# STM32G07x register map
File version: 1.3
CPU: CM0+ r0p0, little endian, no MPU, no FPU, 3 interrupt priority bits
Registers are 32-bit, read-write, reset 0x0 unless marked. A register's access mark holds for its fields unless they carry their own. Offsets are from the block's base; [hi:lo] are bit positions; 'fields as' and 'values as' point back to an identical list.

## RTC — Real-time clock
Base 0x40002800
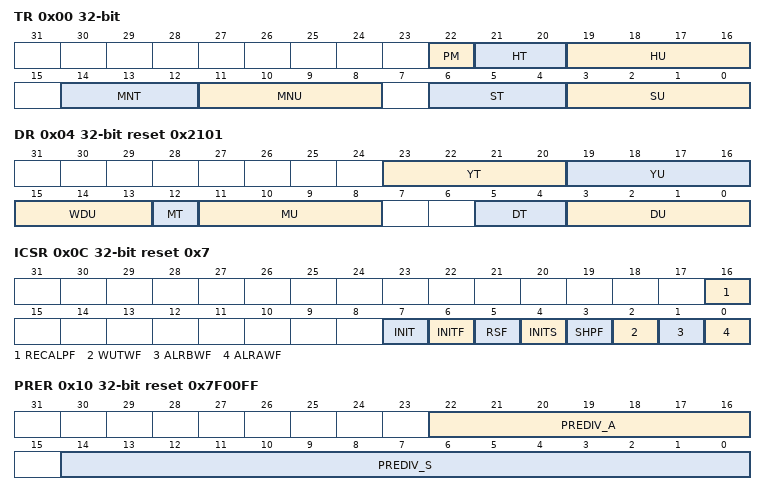
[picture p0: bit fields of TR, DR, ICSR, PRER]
0x00 TR — time register
  [22] PM — AM/PM notation
  [21:20] HT — Hour tens in BCD format
  [19:16] HU — Hour units in BCD format
  [14:12] MNT — Minute tens in BCD format
  [11:8] MNU — Minute units in BCD format
  [6:4] ST — Second tens in BCD format
  [3:0] SU — Second units in BCD format
0x04 DR reset 0x2101 — date register
  [23:20] YT — Year tens in BCD format
  [19:16] YU — Year units in BCD format
  [15:13] WDU — Week day units
  [12] MT — Month tens in BCD format
  [11:8] MU — Month units in BCD format
  [5:4] DT — Date tens in BCD format
  [3:0] DU — Date units in BCD format
0x08 SSR ro — sub second register
  [15:0] SS — Sub second value
0x0C ICSR access per field reset 0x7 — initialization and status register
  [16] RECALPF ro — Recalibration pending Flag
  [7] INIT rw — Initialization mode
  [6] INITF ro — Initialization flag
  [5] RSF rw — Registers synchronization flag
  [4] INITS ro — Initialization status flag
  [3] SHPF rw — Shift operation pending
  [2] WUTWF ro — Wakeup timer write flag
  [1] ALRBWF ro — Alarm B write flag
  [0] ALRAWF ro — Alarm A write flag
0x10 PRER reset 0x7F00FF — prescaler register
  [22:16] PREDIV_A — Asynchronous prescaler factor
  [14:0] PREDIV_S — Synchronous prescaler factor
0x14 WUTR reset 0xFFFF — wakeup timer register
  [15:0] WUT — Wakeup auto-reload value bits
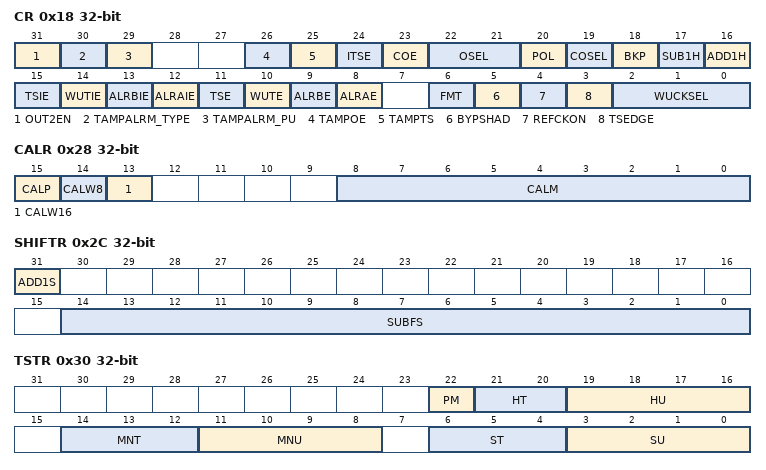
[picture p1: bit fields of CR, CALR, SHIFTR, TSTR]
0x18 CR — control register
  [31] OUT2EN, [30] TAMPALRM_TYPE, [29] TAMPALRM_PU, [26] TAMPOE, [25] TAMPTS, [24] ITSE, [23] COE, [22:21] OSEL, [20] POL, [19] COSEL, [18] BKP, [17] SUB1H, [16] ADD1H, [15] TSIE, [14] WUTIE, [13] ALRBIE, [12] ALRAIE, [11] TSE, [10] WUTE, [9] ALRBE, [8] ALRAE, [6] FMT, [5] BYPSHAD, [4] REFCKON, [3] TSEDGE, [2:0] WUCKSEL
0x24 WPR wo — write protection register
  [7:0] KEY — Write protection key
0x28 CALR — calibration register
  [15] CALP — Increase frequency of RTC by 488.5 ppm
  [14] CALW8 — Use an 8-second calibration cycle period
  [13] CALW16 — Use a 16-second calibration cycle period
  [8:0] CALM — Calibration minus
0x2C SHIFTR wo — shift control register
  [31] ADD1S — Add one second
  [14:0] SUBFS — Subtract a fraction of a second
0x30 TSTR ro — time stamp time register
  fields as TR
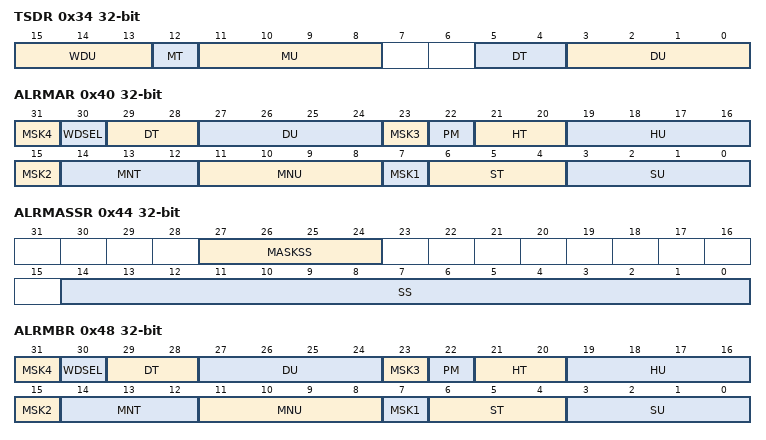
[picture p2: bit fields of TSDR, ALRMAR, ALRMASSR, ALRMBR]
0x34 TSDR ro — time stamp date register
  [15:13] WDU — Week day units
  [12] MT — Month tens in BCD format
  [11:8] MU — Month units in BCD format
  [5:4] DT — Date tens in BCD format
  [3:0] DU — Date units in BCD format
0x38 TSSSR ro — timestamp sub second register
  [15:0] SS — Sub second value
0x40 ALRMAR — alarm A register
  [31] MSK4 — Alarm A date mask
  [30] WDSEL — Week day selection
  [29:28] DT — Date tens in BCD format
  [27:24] DU — Date units or day in BCD format
  [23] MSK3 — Alarm A hours mask
  [22] PM — AM/PM notation
  [21:20] HT — Hour tens in BCD format
  [19:16] HU — Hour units in BCD format
  [15] MSK2 — Alarm A minutes mask
  [14:12] MNT — Minute tens in BCD format
  [11:8] MNU — Minute units in BCD format
  [7] MSK1 — Alarm A seconds mask
  [6:4] ST — Second tens in BCD format
  [3:0] SU — Second units in BCD format
0x44 ALRMASSR — alarm A sub second register
  [27:24] MASKSS — Mask the most-significant bits starting at this bit
  [14:0] SS — Sub seconds value
0x48 ALRMBR — alarm B register
  [31] MSK4 — Alarm B date mask
  [30] WDSEL — Week day selection
  [29:28] DT — Date tens in BCD format
  [27:24] DU — Date units or day in BCD format
  [23] MSK3 — Alarm B hours mask
  [22] PM — AM/PM notation
  [21:20] HT — Hour tens in BCD format
  [19:16] HU — Hour units in BCD format
  [15] MSK2 — Alarm B minutes mask
  [14:12] MNT — Minute tens in BCD format
  [11:8] MNU — Minute units in BCD format
  [7] MSK1 — Alarm B seconds mask
  [6:4] ST — Second tens in BCD format
  [3:0] SU — Second units in BCD format
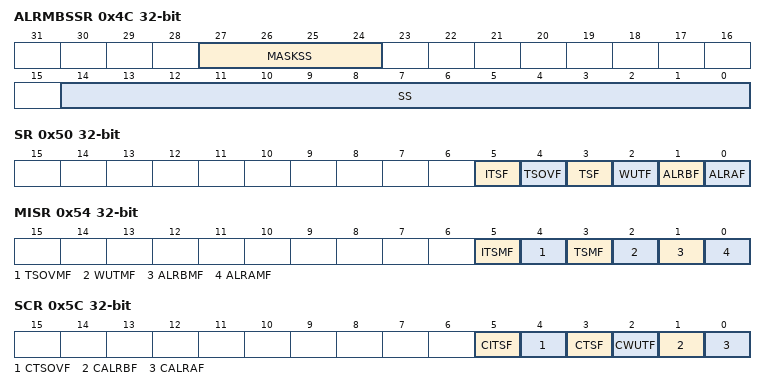
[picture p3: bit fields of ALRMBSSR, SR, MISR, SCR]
0x4C ALRMBSSR — alarm B sub second register
  fields as ALRMASSR
0x50 SR ro — status register
  [5] ITSF, [4] TSOVF, [3] TSF, [2] WUTF, [1] ALRBF, [0] ALRAF
0x54 MISR ro — masked interrupt status register
  [5] ITSMF, [4] TSOVMF, [3] TSMF, [2] WUTMF, [1] ALRBMF, [0] ALRAMF
0x5C SCR — status clear register
  [5] CITSF, [4] CTSOVF, [3] CTSF, [2] CWUTF, [1] CALRBF, [0] CALRAF
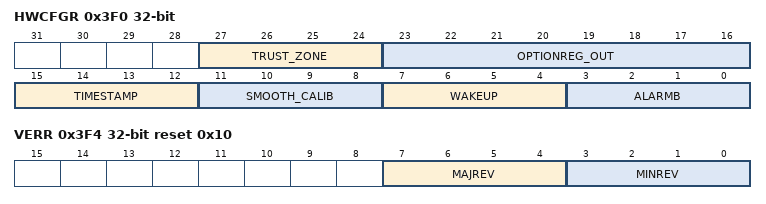
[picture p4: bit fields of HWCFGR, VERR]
0x3F0 HWCFGR — hardware configuration register
  [27:24] TRUST_ZONE, [23:16] OPTIONREG_OUT, [15:12] TIMESTAMP, [11:8] SMOOTH_CALIB, [7:4] WAKEUP, [3:0] ALARMB
0x3F4 VERR ro reset 0x10 — EXTI IP Version register
  [7:4] MAJREV — Major Revision number
  [3:0] MINREV — Minor Revision number
0x3F8 IPIDR ro reset 0x120033 — EXTI Identification register
  [31:0] IPID — IP Identification
0x3FC SIDR ro reset 0xA3C5DD01 — EXTI Size ID register
  [31:0] SID — Size Identification
